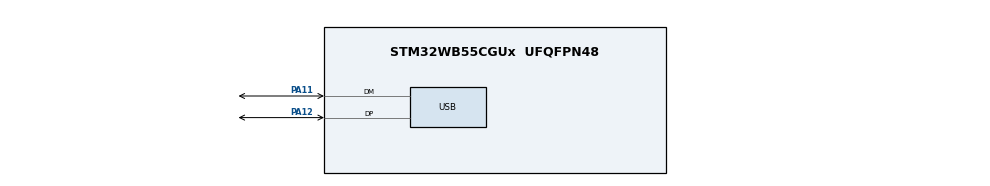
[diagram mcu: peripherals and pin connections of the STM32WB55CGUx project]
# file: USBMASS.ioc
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Mcu.Family=STM32WB
Mcu.Name=STM32WB55CGUx
Mcu.Package=UFQFPN48
NVIC.PriorityGroup=NVIC_PRIORITYGROUP_4
NVIC.USB_LP_IRQn=true\:0\:0\:false\:false\:true\:true\:true\:true
PA11.Mode=Device
PA11.Signal=USB_DM
PA12.Mode=Device
PA12.Signal=USB_DP
ProjectManager.HeapSize=0x2000
ProjectManager.StackSize=0x400
ProjectManager.TargetToolchain=STM32CubeIDE
RCC.ADCFreq_Value=48000000
RCC.AHBFreq_Value=32000000
RCC.APB1CLKDivider=RCC_HCLK_DIV4
RCC.APB1Freq_Value=8000000
RCC.APB1TimFreq_Value=16000000
RCC.APB2CLKDivider=RCC_HCLK_DIV4
RCC.APB2Freq_Value=8000000
RCC.APB2TimFreq_Value=16000000
RCC.APB3Freq_Value=16000000
RCC.CK48CLockSelection=RCC_USBCLKSOURCE_HSI48
RCC.Cortex2_Div=SYSTICK_CLKSOURCE_HCLK_DIV8
RCC.CortexFreq_Value=32000000
RCC.HCLKFreq_Value=32000000
RCC.HSE_VALUE=32000000
RCC.HSI48_VALUE=48000000
RCC.HSI_VALUE=16000000
RCC.MSIClockRange=RCC_MSIRANGE_10
RCC.PLLM=RCC_PLLM_DIV2
RCC.PLLN=32
RCC.PLLSAI1N=6
RCC.SMPSDivider=1
RCC.SYSCLKFreq_VALUE=32000000
RCC.USBFreq_Value=48000000
RCC.VCOOutputFreq_Value=512000000
USB_DEVICE.CLASS_NAME_FS=MSC
USB_DEVICE.VirtualMode=Msc
USB_DEVICE.VirtualModeFS=Msc_FS
VP_MEMORYMAP_VS_MEMORYMAP.Mode=CurAppReg
VP_USB_DEVICE_VS_USB_DEVICE_MSC_FS.Mode=MSC_FS
board=custom

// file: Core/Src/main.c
/* USER CODE BEGIN Header */
/**
  ******************************************************************************
  * @file           : main.c
  * @brief          : Main program body
  ******************************************************************************
  * @attention
  *
  * Copyright (c) 2025 STMicroelectronics.
  * All rights reserved.
  *
  * This software is licensed under terms that can be found in the LICENSE file
  * in the root directory of this software component.
  * If no LICENSE file comes with this software, it is provided AS-IS.
  *
  ******************************************************************************
  */
/* USER CODE END Header */
#include "main.h"
#include "usb_device.h"
#include "stm32wbxx_ll_rcc.h"

/* USER CODE BEGIN Includes */
extern PCD_HandleTypeDef hpcd_USB_FS;
/* USER CODE END Includes */

/* USER CODE BEGIN PD */
/*
#define BUTTON_PIN GPIO_PIN_0
#define BUTTON_PORT GPIOA
#define PIEZO_PIN GPIO_PIN_2
#define PIEZO_PORT GPIOB
#define Butt_TIMEOUT_MS 2000
#define BOOT_ADD 0x1FFF0000 //0x1FFF0000 stm32wb55 bootloader address
#define BootJumpTime 3000
*/
/* USER CODE END PD */

void SystemClock_Config(void);
void PeriphCommonClock_Config(void);
static void MX_GPIO_Init(void);
/* USER CODE BEGIN PFP */
//void PlayBeep(uint32_t duration_ms);
//void JumpToBootloader(void);
/* USER CODE END PFP */

int main(void)
{

  /* MCU Configuration--------------------------------------------------------*/

  /* Reset of all peripherals, Initializes the Flash interface and the Systick. */
  HAL_Init();

  /* Configure the system clock */
  SystemClock_Config();

  /* Configure the peripherals common clocks */
  PeriphCommonClock_Config();

  /* Initialize all configured peripherals */
  MX_GPIO_Init();
  HAL_Delay(1000);
  MX_USB_Device_Init();
  HAL_Delay(1000);
  /* USER CODE BEGIN 2 */
  //HAL_PWREx_EnableVddUSB();

   // PlayBeep(100);
////////////usb reinicializacia/////////////
 // 	  MX_USB_Device_DeInit();
  	  HAL_PCD_DevDisconnect(&hpcd_USB_FS);
      HAL_Delay(100);
      HAL_PCD_Stop(&hpcd_USB_FS);
      HAL_PCD_DeInit(&hpcd_USB_FS);
      HAL_Delay(2000);
      MX_USB_Device_Init();
      MSC_BOT_Reset (&hpcd_USB_FS);
  //HAL_PCD_Init(&hpcd_USB_FS);
  //HAL_PCD_Start(&hpcd_USB_FS);
  //MX_USB_Device_Init();

///////////koniec reinitu//////////
  //function for mcu bootloader jump after power inicialisation
  /*
   uint32_t buttonPressStartTime = 0;
   uint32_t TimeoutCounter = 0;
   uint8_t buttonHeld = 0;
   TimeoutCounter = HAL_GetTick();
   //till boot jump time period is gone, stay in the loop and read the button
   while ( HAL_GetTick() - TimeoutCounter <= BootJumpTime ) {
 	  //read the button. if button is zero(pulldown) start the countdown
 	  	  if (HAL_GPIO_ReadPin(BUTTON_PORT, BUTTON_PIN) == GPIO_PIN_RESET) {
 	  	             if (!buttonHeld) {
 	  	                 buttonHeld = 1;
 	  	                 buttonPressStartTime = HAL_GetTick();
 	  	             //if we pass 2s debouncing play beep and jump to the bootloader
 	  	             } else if (HAL_GetTick() - buttonPressStartTime >= Butt_TIMEOUT_MS) {
 	  	                 PlayBeep(1000); // pay beep for 1 sec
 	  	                 JumpToBootloader();
 	  	             }
 	  	  }
 	  	  else {
 	  	             buttonHeld = 0; // if button was pressed shorter time release the flag

 	  	  }

   }
   */
   //HAL_PWREx_EnableVddUSB();

  // MX_USB_Device_Init();

   //PlayBeep(300);

  /* USER CODE END 2 */

  /* Infinite loop */
  while (1)
  {

  }
}

void SystemClock_Config(void)
{
  RCC_OscInitTypeDef RCC_OscInitStruct = {0};
  RCC_ClkInitTypeDef RCC_ClkInitStruct = {0};

  /** Configure the main internal regulator output voltage
  */
  __HAL_PWR_VOLTAGESCALING_CONFIG(PWR_REGULATOR_VOLTAGE_SCALE1);

  /** Initializes the RCC Oscillators according to the specified parameters
  * in the RCC_OscInitTypeDef structure.
  */
  RCC_OscInitStruct.OscillatorType = RCC_OSCILLATORTYPE_HSI48|RCC_OSCILLATORTYPE_HSI
                              |RCC_OSCILLATORTYPE_MSI;
  RCC_OscInitStruct.HSIState = RCC_HSI_ON;
  RCC_OscInitStruct.MSIState = RCC_MSI_ON;
  RCC_OscInitStruct.HSI48State = RCC_HSI48_ON;
  RCC_OscInitStruct.HSICalibrationValue = RCC_HSICALIBRATION_DEFAULT;
  RCC_OscInitStruct.MSICalibrationValue = RCC_MSICALIBRATION_DEFAULT;
  RCC_OscInitStruct.MSIClockRange = RCC_MSIRANGE_10;
  RCC_OscInitStruct.PLL.PLLState = RCC_PLL_NONE;
  if (HAL_RCC_OscConfig(&RCC_OscInitStruct) != HAL_OK)
  {
    Error_Handler();
  }

  /** Configure the SYSCLKSource, HCLK, PCLK1 and PCLK2 clocks dividers
  */
  RCC_ClkInitStruct.ClockType = RCC_CLOCKTYPE_HCLK4|RCC_CLOCKTYPE_HCLK2
                              |RCC_CLOCKTYPE_HCLK|RCC_CLOCKTYPE_SYSCLK
                              |RCC_CLOCKTYPE_PCLK1|RCC_CLOCKTYPE_PCLK2;
  RCC_ClkInitStruct.SYSCLKSource = RCC_SYSCLKSOURCE_MSI;
  RCC_ClkInitStruct.AHBCLKDivider = RCC_SYSCLK_DIV1;
  RCC_ClkInitStruct.APB1CLKDivider = RCC_HCLK_DIV4;
  RCC_ClkInitStruct.APB2CLKDivider = RCC_HCLK_DIV4;
  RCC_ClkInitStruct.AHBCLK2Divider = RCC_SYSCLK_DIV1;
  RCC_ClkInitStruct.AHBCLK4Divider = RCC_SYSCLK_DIV1;

  if (HAL_RCC_ClockConfig(&RCC_ClkInitStruct, FLASH_LATENCY_1) != HAL_OK)
  {
    Error_Handler();
  }
}

void PeriphCommonClock_Config(void)
{
  RCC_PeriphCLKInitTypeDef PeriphClkInitStruct = {0};

  /** Initializes the peripherals clock
  */
  PeriphClkInitStruct.PeriphClockSelection = RCC_PERIPHCLK_SMPS;
  PeriphClkInitStruct.SmpsClockSelection = RCC_SMPSCLKSOURCE_HSI;
  PeriphClkInitStruct.SmpsDivSelection = RCC_SMPSCLKDIV_RANGE0;

  if (HAL_RCCEx_PeriphCLKConfig(&PeriphClkInitStruct) != HAL_OK)
  {
    Error_Handler();
  }
}

static void MX_GPIO_Init(void)
{

  /* GPIO Ports Clock Enable */
  __HAL_RCC_GPIOA_CLK_ENABLE();

}

/* USER CODE BEGIN 4 */
/*
/////////////////this function generates acoustic signal on mcu GPIO pin via LPTIM//////////////////////

void PlayBeep(uint32_t duration_ms) {
	uint32_t period = 999;  // 1 kHz (f=clk 4MHz/999)
	uint32_t pulse = 500;   // 50% duty cycle (D=pulse/period)
	// Spusti časovač na generovanie PWM
    HAL_LPTIM_PWM_Start(&hlptim1, period, pulse);

    // Čakaj, kým uplynie trvanie zvuku
    HAL_Delay(duration_ms);

    // Zastav časovač
    HAL_LPTIM_PWM_Stop(&hlptim1);
}

////////////////////this function releases all peripherials and jumps into bootloader/////////////////////////
void JumpToBootloader(void) {

    // Vypnutie prerušení
    __disable_irq();

    // Reset USB
    USB->CNTR = 0x0003;

    // Resetovanie periférií
    __HAL_RCC_GPIOC_CLK_DISABLE();
    __HAL_RCC_GPIOB_CLK_DISABLE();
    __HAL_RCC_GPIOA_CLK_DISABLE();
    //USB->CNTR = 0x0003;
    HAL_LPTIM_DeInit(&hlptim1);
    HAL_RCC_DeInit();
   // HAL_DeInit();
    // resetne systivk
    SysTick->CTRL = 0;
    SysTick->LOAD = 0;
    SysTick->VAL = 0;
    // Clear all interrupt bits
      for (uint8_t i = 0; i < sizeof(NVIC->ICER) / sizeof(NVIC->ICER[0]); i++)
      {
        NVIC->ICER[i] = 0xFFFFFFFF;
        NVIC->ICPR[i] = 0xFFFFFFFF;
      }

      // Re-enable all interrupts //

      __enable_irq();

      // Set up the jump to boot loader address + 4 /
      uint32_t jump_address = *(__IO uint32_t *)(BOOT_ADD + 4);

      // Set the main stack pointer to the boot loader stack /
      __set_MSP(*(uint32_t *)BOOT_ADD);

      // Call the function to jump to boot loader location /
      void (*boot_load)(void) = (void (*)(void))(jump_address);

      //remap memory
      SYSCFG->MEMRMP = 0x01;

      // Now jump to the boot loader
      boot_load();
      // Jump is done successfully
}
*/
///////////////////end of bootloader function////////////////////////
/* USER CODE END 4 */

void Error_Handler(void)
{
  __disable_irq();
  while (1)
  {
  }
}
